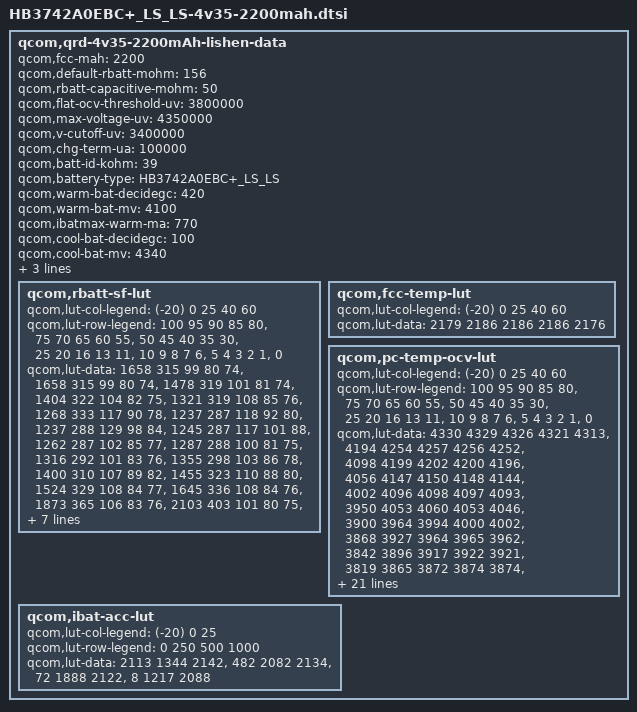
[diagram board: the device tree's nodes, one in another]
/* Copyright (c) 2013, The Linux Foundation. All rights reserved.
 *
 * This program is free software; you can redistribute it and/or modify
 * it under the terms of the GNU General Public License version 2 and
 * only version 2 as published by the Free Software Foundation.
 *
 * This program is distributed in the hope that it will be useful,
 * but WITHOUT ANY WARRANTY; without even the implied warranty of
 * MERCHANTABILITY or FITNESS FOR A PARTICULAR PURPOSE.  See the
 * GNU General Public License for more details.
 */

qcom,qrd-4v35-2200mAh-lishen-data {
	qcom,fcc-mah = <2200>;
	qcom,default-rbatt-mohm = <156>;
	qcom,rbatt-capacitive-mohm = <50>;
	qcom,flat-ocv-threshold-uv = <3800000>;
	qcom,max-voltage-uv = <4350000>;
	qcom,v-cutoff-uv = <3400000>;
	qcom,chg-term-ua = <100000>;
	qcom,batt-id-kohm = <39>;
	qcom,battery-type = "HB3742A0EBC+_LS_LS";

	qcom,warm-bat-decidegc = <420>;
	qcom,warm-bat-mv = <4100>;
	qcom,ibatmax-warm-ma = <770>;

	qcom,cool-bat-decidegc = <100>;
	qcom,cool-bat-mv = <4340>;
	qcom,ibatmax-cool-ma = <600>;

	qcom,hot-bat-decidegc = <520>;
	qcom,cold-bat-decidegc = <0>;
	qcom,rbatt-sf-lut {
		qcom,lut-col-legend = <(-20) 0 25 40 60>;
		qcom,lut-row-legend = <100 95 90 85 80>,
				<75 70 65 60 55>,
				<50 45 40 35 30>,
				<25 20 16 13 11>,
				<10 9 8 7 6>,
				<5 4 3 2 1>,
				<0>;
		qcom,lut-data =	<1658 315 99 80 74>,
				<1658 315 99 80 74>,
				<1478 319 101 81 74>,
				<1404 322 104 82 75>,
				<1321 319 108 85 76>,
				<1268 333 117 90 78>,
				<1237 287 118 92 80>,
				<1237 288 129 98 84>,
				<1245 287 117 101 88>,
				<1262 287 102 85 77>,
				<1287 288 100 81 75>,
				<1316 292 101 83 76>,
				<1355 298 103 86 78>,
				<1400 310 107 89 82>,
				<1455 323 110 88 80>,
				<1524 329 108 84 77>,
				<1645 336 108 84 76>,
				<1873 365 106 83 76>,
				<2103 403 101 80 75>,
				<2208 426 101 82 76>,
				<2204 411 102 83 76>,
				<1880 388 104 84 78>,
				<2066 396 109 87 79>,
				<2304 406 113 89 81>,
				<2609 412 116 90 80>,
				<3031 422 112 86 76>,
				<3671 442 109 85 78>,
				<4829 472 112 88 79>,
				<7561 534 121 96 87>,
				<15122 1068 224 154 138>,
				<30245 2136 448 308 275>;
	};

	qcom,fcc-temp-lut {
		qcom,lut-col-legend = <(-20) 0 25 40 60>;
		qcom,lut-data = <2179 2186 2186 2186 2176>;
	};

	qcom,pc-temp-ocv-lut {
		qcom,lut-col-legend = <(-20) 0 25 40 60>;
		qcom,lut-row-legend = <100 95 90 85 80>,
				<75 70 65 60 55>,
				<50 45 40 35 30>,
				<25 20 16 13 11>,
				<10 9 8 7 6>,
				<5 4 3 2 1>,
				<0>;
		qcom,lut-data = <4330 4329 4326 4321 4313>,
				<4194 4254 4257 4256 4252>,
				<4098 4199 4202 4200 4196>,
				<4056 4147 4150 4148 4144>,
				<4002 4096 4098 4097 4093>,
				<3950 4053 4060 4053 4046>,
				<3900 3964 3994 4000 4002>,
				<3868 3927 3964 3965 3962>,
				<3842 3896 3917 3922 3921>,
				<3819 3865 3872 3874 3874>,
				<3800 3837 3843 3844 3844>,
				<3782 3812 3820 3821 3820>,
				<3766 3791 3801 3802 3801>,
				<3750 3776 3785 3785 3784>,
				<3736 3762 3772 3768 3762>,
				<3720 3744 3756 3749 3738>,
				<3700 3724 3737 3730 3716>,
				<3680 3712 3714 3706 3694>,
				<3659 3705 3695 3686 3675>,
				<3641 3700 3689 3681 3669>,
				<3630 3696 3688 3680 3668>,
				<3618 3691 3687 3679 3667>,
				<3602 3684 3685 3678 3666>,
				<3582 3674 3682 3675 3662>,
				<3557 3655 3672 3665 3651>,
				<3524 3624 3646 3637 3620>,
				<3482 3581 3601 3590 3572>,
				<3422 3519 3538 3527 3510>,
				<3341 3426 3450 3441 3426>,
				<3225 3289 3314 3304 3293>,
				<3010 3000 3000 3000 3000>;
	};
	qcom,ibat-acc-lut {
		qcom,lut-col-legend = <(-20) 0 25>;
		qcom,lut-row-legend = <0 250 500 1000>;
		qcom,lut-data = <2113 1344 2142>,
				<482 2082 2134>,
				<72 1888 2122>,
				<8 1217 2088>;
    };
};
